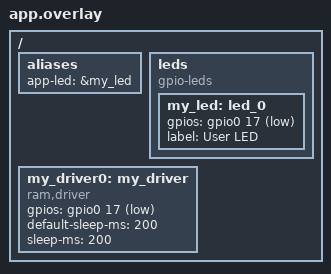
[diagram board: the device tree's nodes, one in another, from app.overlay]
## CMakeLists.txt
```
cmake_minimum_required(VERSION 3.20.0)

list(APPEND BOARD_ROOT ${CMAKE_CURRENT_SOURCE_DIR})
find_package(Zephyr REQUIRED)
project(my_zephyr_app)

target_sources(app PRIVATE src/main.cpp)
add_subdirectory(drivers/my_driver)
```

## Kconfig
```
config DEBUG_MY_BOARD
    bool "Enable debug on my board"
    default n
    help
        enable debug on the board with LEDs  

menuconfig LED_SUBSYSTEM
    bool "LED Subsystem"
    default y

if LED_SUBSYSTEM

    config APP_HEART_BEAT_PERIOD_MS
        int "Heartbeat period (ms)"
        default 500
        range 100 2000
        help 
            set the heart beat blink period between 100 and 2000
            (500 is the default)

    choice 
        prompt "LED blink speed"
        default BLINK_SLEEP_1000MS

    config BLINK_SLEEP_250MS
        bool "SuperFast"

    config BLINK_SLEEP_500MS
        bool "Fast"

    config BLINK_SLEEP_1000MS
        bool "Normal"

    config BLINK_SLEEP_2000MS    
        bool "Slow"
        
    endchoice

    config BLINK_SLEEP_TIME_MS
        int 
        default 250 if BLINK_SLEEP_250MS
        default 500 if BLINK_SLEEP_500MS
        default 1000 if BLINK_SLEEP_1000MS
        default 2000 if BLINK_SLEEP_2000MS
        range 100 5000
        help 
            set the blink sleep time (ms) between 100 and 5000 
            (1000 is the default)

    menuconfig ADVANCED_LED_SETTINGS
        bool "Advanced LED settings"
        default y

    if ADVANCED_LED_SETTINGS

        config LED_BRIGHTNESS
            int "LED brightness (0-100)"
            default 100
            range 0 100
            help 
                set the LED brightness between 0 and 100
                (100 is the default)            

        config LED_FADE_DURATION
            int "LED fade duration(ms)"
            default 500
            range 0 5000
            help 
                set the LED fade duration between 0 and 5000 ms
                (500 is the default)    

        menu "Expert settings"
            visible if DEBUG_MY_BOARD
            config LED_DEBUG
                bool "Enable LED debugging"
                default y
                help
                    enable LED debugging

            config CUSTOM_BLINK_PATTERN
                bool "Custom blink pattern"
                default y
                help
                    enable the custom blink pattern                
        endmenu


    endif # ADVANCED_LED_SETTINGS    

endif # LED_SUBSYSTEM

source "Kconfig.zephyr"
rsource "drivers/my_driver/Kconfig"
```

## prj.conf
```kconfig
CONFIG_GPIO=y
CONFIG_LOG=y
CONFIG_PRINTK=y
CONFIG_SHELL=y

CONFIG_HEAP_MEM_POOL_SIZE=4096
CONFIG_SENSOR=y

CONFIG_MY_DRIVER=y

# Enables the console driver
CONFIG_CONSOLE=y

# Directs printf/printk to the console driver
CONFIG_UART_CONSOLE=y

# Enables the UART driver for the ESP32
CONFIG_SERIAL=y

# Adds a 2-second delay at boot so you have time to connect your terminal
CONFIG_BOOT_BANNER=y
```

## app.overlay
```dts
/ {
    aliases {
        app-led = &my_led;
    };

    leds {
        compatible = "gpio-leds";
        my_led: led_0 {
            /* Use &gpio0, then the pin number (17), then the flag */
            gpios = <&gpio0 17 GPIO_ACTIVE_LOW>;
            label = "User LED";
        };

    };

    my_driver0: my_driver {
        compatible = "ram,driver";
        gpios = <&gpio0 17 GPIO_ACTIVE_LOW>;
        default-sleep-ms = <200>;
        sleep-ms = <200>;
        status = "okay";
    };
};
```

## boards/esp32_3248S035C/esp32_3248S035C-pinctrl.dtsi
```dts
#include <zephyr/dt-bindings/pinctrl/esp-pinctrl-common.h>
#include <zephyr/dt-bindings/pinctrl/esp32-pinctrl.h>
#include <zephyr/dt-bindings/pinctrl/esp32-gpio-sigmap.h>

&pinctrl {
	uart0_default: uart0_default {
		group1 {
			pinmux = <UART0_TX_GPIO1>;
			output-high;
		};

		group2 {
			pinmux = <UART0_RX_GPIO3>;
			bias-pull-up;
		};
	};
};
```

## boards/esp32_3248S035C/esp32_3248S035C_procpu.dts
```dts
/dts-v1/;

#include <espressif/esp32/esp32_wrover_e_n4r8.dtsi>
#include "esp32_3248S035C-pinctrl.dtsi"
#include <zephyr/dt-bindings/input/input-event-codes.h>
#include <espressif/partitions_0x1000_amp.dtsi>

/ {
	model = "Cheap Yellow Display ESP32-3248S035C PROCPU";
	compatible = "espressif,esp32";

	aliases {
		uart-0 = &uart0;
	};


	chosen {
		zephyr,sram = &sram1;
		zephyr,console = &uart0;
		zephyr,shell-uart = &uart0;
		zephyr,flash = &flash0;
		zephyr,code-partition = &slot0_partition;
	};
};

&uart0 {
	status = "okay";
	current-speed = <115200>;
	pinctrl-0 = <&uart0_default>;
	pinctrl-names = "default";
};

&gpio0 {
	status = "okay";
};
```

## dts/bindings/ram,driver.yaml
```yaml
description: custom driver for lesson 6 homework
compatible: "ram,driver"
include: base.yaml
properties:
  calibration:
    type: int
    required: false
    description: Calibration value for the sensor
  gpios:
    type: phandle-array
    required: true
    description: GPIO spec for LED controlling
  default-sleep-ms:
    type: int
    required: true
    description: Default duration for k_msleep (in ms) to return from calls to turn On/Off in the driver    
  sleep-ms:
    type: int
    required: true
    description: Duration for k_msleep (in ms) to return from calls to turn On/Off in the driver    
```

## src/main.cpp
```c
#include <stdio.h>

#include <zephyr/drivers/gpio.h>
#include <zephyr/kernel.h>
#include <zephyr/logging/log.h>

#include <zephyr/drivers/sensor.h>

#include "my_driver.h"

/* The devicetree node identifier for the "led0" alias. */
#define LED_NODE DT_ALIAS(app_led)

/* Lecture 7 - Home task 2 - WITH circular LED blinking - 
   LED blinking sleep interval can be set by subcmd 'set':

    uart:~$ sensor set my_driver 20
    SUB CMD set <device name> <sleep value in ms>
    Value 20 is out of range! Expected bounds: [50 to 2500] ms

    uart:~$ sensor set my_driver 500
    SUB CMD set <device name> <sleep value in ms>
    Sleep interval successfully updated to 500 ms
    [00:02:39.191,000] <inf> sensor_ram_driver:  sleep_ms updated to 500 

    uart:~$ sensor set my_driver 2500
    SUB CMD set <device name> <sleep value in ms>
    Sleep interval successfully updated to 2500 ms
    [00:02:46.331,000] <inf> sensor_ram_driver:  sleep_ms updated to 2500 

*/
#define LECTURE_NR 72 /* Lecture 7 - Home task 2 */

static const struct gpio_dt_spec led = GPIO_DT_SPEC_GET(LED_NODE, gpios);

LOG_MODULE_REGISTER(main, LOG_LEVEL_INF);

int main(void)
{
    #if (LECTURE_NR >= 6)
    struct sensor_value value;
    const struct device *mydev = DEVICE_DT_GET(DT_NODELABEL(my_driver0));

    if (!device_is_ready(mydev)) {
        LOG_ERR("Error: My driver device is not ready!\n");
        return -ENODEV; 
    }
    #endif

    uint32_t default_sleep_ms = my_get_sleep_ms(mydev);

    bool led_state = true;
    #if ((LECTURE_NR == 6) || (LECTURE_NR == 72))
    uint32_t sequential_max = 5; // max number of changes we allow sleep to change (always by double)
    uint32_t sleep_iteration_change = 0;
    #endif
    uint32_t current_sleep_ms = 0;

    #if (LECTURE_NR < 6) // lessons previous to custom driver
    if (!gpio_is_ready_dt(&led)) return 0;

    if (gpio_pin_configure_dt(&led, GPIO_OUTPUT_ACTIVE) < 0) return 0;
    #endif

    LOG_INF("Hello World! %s\n", CONFIG_BOARD_TARGET);

    while (1) {

        #if (LECTURE_NR < 6) // lessons previous to custom driver
        if (gpio_pin_toggle_dt(&led) < 0) return 0;
        #endif

        led_state = !led_state;

        #if ((LECTURE_NR == 6) || (LECTURE_NR == 72))

        if (led_state)
            (void)sensor_sample_fetch(mydev);
        else
            (void)sensor_channel_get(mydev, SENSOR_CHAN_AMBIENT_TEMP, &value);

        #endif

        #if (LECTURE_NR <= 6)
        LOG_INF("LED state: %s", led_state ? "ON" : "OFF");
        #endif

        current_sleep_ms = my_get_sleep_ms(mydev);
        k_msleep(current_sleep_ms);

        #if (LECTURE_NR == 6)
        // double the sleep_ms each time until sequential_max is reached
        if (++sleep_iteration_change <= sequential_max)
        {
            my_set_sleep_ms(mydev, 2*current_sleep_ms);
            LOG_INF("_iteration: %d  sleep_ms_after doubled: %d ", sleep_iteration_change, my_get_sleep_ms(mydev));
        }
        else
        {   // reset to initial condition to restart the cycle
            sleep_iteration_change = 0;
            my_set_sleep_ms(mydev, default_sleep_ms);
            LOG_INF("  Reset to default sleep value: ", my_get_sleep_ms(mydev));
        }
        #endif

    }
    return 0;
}
```
